# MCXN236 register map
Vendor: nxp.com; File version: 1.0
CPU: CM33 r2p0, little endian, MPU, FPU, VTOR, 3 interrupt priority bits
Registers are 32-bit, read-write, reset 0x0 unless marked. A register's access mark holds for its fields unless they carry their own. Offsets are from the block's base; [hi:lo] are bit positions; {n}, {i} and the like mark numbered series; 'fields as' and 'values as' point back to an identical list.

## PUF_CTRL — PUF Key Context Management
Base 0x4002C000; alternate view of PUF
Same registers: PUF_CTRL_ALIAS1 0x4002D000 (alternate view of PUF_ALIAS1), PUF_CTRL_ALIAS2 0x4002E000 (alternate view of PUF_ALIAS2), PUF_CTRL_ALIAS3 0x4002F000 (alternate view of PUF_ALIAS3)
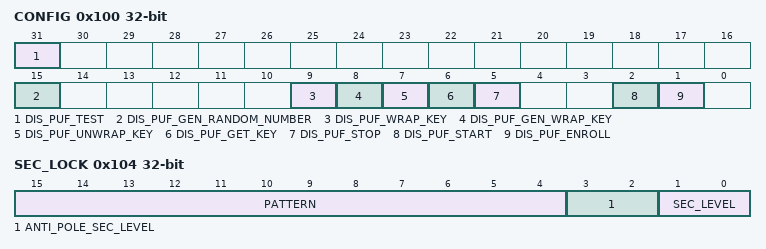
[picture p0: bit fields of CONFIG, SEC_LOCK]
0x100 CONFIG — PUF command blocking configuration
  [all] fields
    0=ENABLE (Command enabled); 1=DISABLE (Command disabled)
  [31] DIS_PUF_TEST — Disable PUF test command
  [15] DIS_PUF_GEN_RANDOM_NUMBER — Disable PUF generate and wrap key command
  [9] DIS_PUF_WRAP_KEY — Disable PUF wrap key command
  [8] DIS_PUF_GEN_WRAP_KEY — Disable PUF generate and wrap key command
  [7] DIS_PUF_UNWRAP_KEY — Disable PUF unwrap key command
  [6] DIS_PUF_GET_KEY — Disable PUF get key command
  [5] DIS_PUF_STOP — Disable PUF stop command
  [2] DIS_PUF_START — Disable PUF start command
  [1] DIS_PUF_ENROLL — Disable PUF enroll command
0x104 SEC_LOCK — Security level lock
  [15:4] PATTERN
  [3:2] ANTI_POLE_SEC_LEVEL — Anti-pole of security level
    0=NONSECURE_NONPRIV_MASTER (Secure and privileged Master); 1=NONSECURE_PRIV_MASTER (Secure and non-privileged Master); 2=SECURE_NONPRIV_MASTER (Non-secure and privileged Master); 3=SECURE_PRIV_MASTER (Non-secure and non-privileged Master)
  [1:0] SEC_LEVEL — Security Level
    0=NONSECURE_NONPRIV_MASTER (Non-secure and non-privileged Master); 1=NONSECURE_PRIV_MASTER (Non-secure and privileged Master); 2=SECURE_NONPRIV_MASTER (Secure and non-privileged Master); 3=SECURE_PRIV_MASTER (Secure and privileged Master)
0x108 APP_CTX_MASK — Application defined context mask
  [31:0] APP_CTX_MASK — Application defined context

## SMARTDMA0 — SmartDMA
Base 0x40033000
0x20 BOOTADR — Boot Address
  [31:2] ADDR — 32-bit boot address, the boot address should be 4-byte aligned.
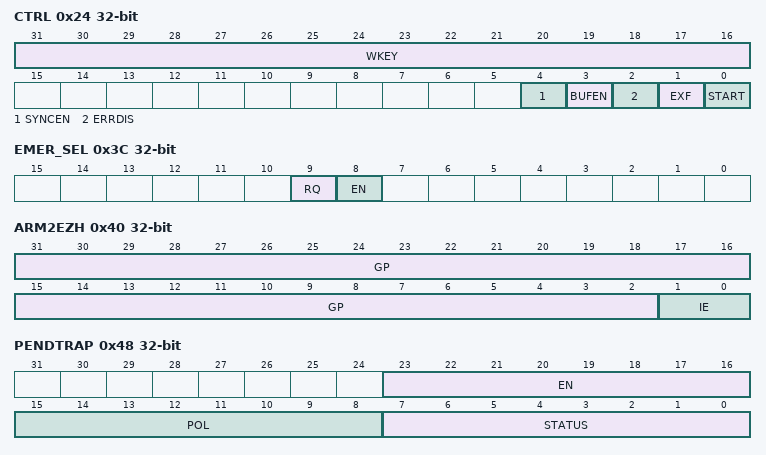
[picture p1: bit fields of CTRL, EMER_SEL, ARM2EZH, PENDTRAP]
0x24 CTRL — Control
  [31:16] WKEY — Write Key
  [4] SYNCEN — Sync Enable
  [3] BUFEN — Buffer Enable
  [2] ERRDIS — Error Disable
  [1] EXF — External Flag
  [0] START — Start Bit Ignition
0x28 PC ro — Program Counter
0x2C SP ro — Stack Pointer
0x30 BREAK_ADDR — Breakpoint Address
  [31:2] ADDR — 32-bit address to swap to EZHB_BREAK_VECT location
0x34 BREAK_VECT — Breakpoint Vector
  [31:2] VEC — Vector address of user debug routine.
0x38 EMER_VECT — Emergency Vector
  [31:2] VEC — Vector address of emergency code routine
0x3C EMER_SEL — Emergency Select
  [9] RQ — Software emergency request
  [8] EN — Emergency code routine
0x40 ARM2EZH — ARM to EZH Interrupt Control
  [31:2] GP — General purpose register bits
  [1:0] IE — Interrupt Enable
0x44 EZH2ARM — EZH to ARM Trigger
  [31:0] GP — General purpose register bits Writing to EZH2ARM triggers the ARM interrupt when ARM2EZH [1:0] == 2h
0x48 PENDTRAP — Pending Trap Control
  [23:16] EN — Enable Pending Trap
  [15:8] POL — Polarity
  [7:0] STATUS — Status Flag or Pending Trap Request

## PORT5 — PORT
Base 0x40042000
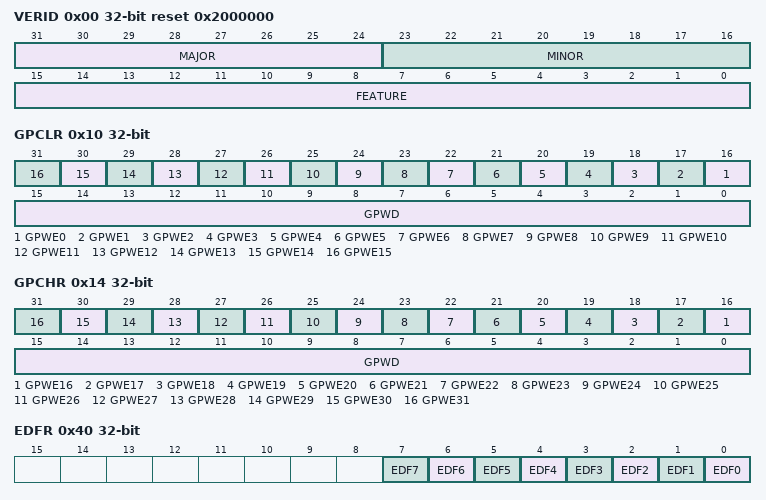
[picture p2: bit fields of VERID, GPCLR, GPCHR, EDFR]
0x00 VERID ro reset 0x2000000 — Version ID
  [31:24] MAJOR — Major Version Number
  [23:16] MINOR — Minor Version Number
  [15:0] FEATURE — Feature Specification Number
    0=Basic implementation
0x10 GPCLR — Global Pin Control Low
  [n+16] GPWE{n} (n=0..15) — Global Pin Write Enable
    0=gpwe0 (Not updated); 1=gpwe1 (Updated)
  [15:0] GPWD — Global Pin Write Data
0x14 GPCHR — Global Pin Control High
  [n] GPWE{n} (n=16..31) — Global Pin Write Enable
    0=gpwe0 (Not updated); 1=gpwe1 (Updated)
  [15:0] GPWD — Global Pin Write Data
0x20 CONFIG — Configuration
  [0] RANGE — Port Voltage Range
    0=1.71 V-3.6 V; 1=2.70 V-3.6 V
0x40 EDFR ro — EFT Detect Flag
  [all] fields
    0=edie0 (No EFT event detected); 1=edie1 (High or/and low EFT event detected)
  [n] EDF{n} (n=0..7) — EFT Detect Flag
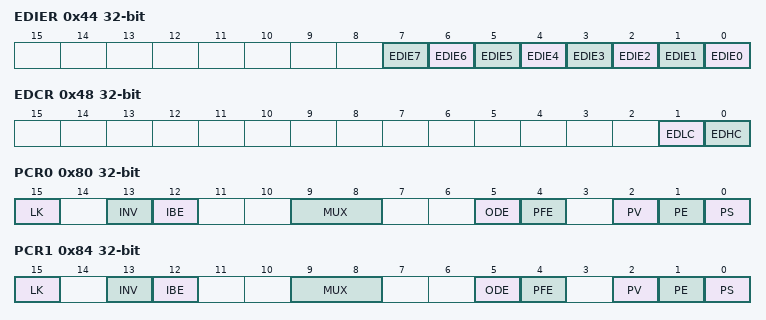
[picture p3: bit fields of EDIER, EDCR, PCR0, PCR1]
0x44 EDIER — EFT Detect Interrupt Enable
  [all] fields
    0=edie0 (Interrupt not generated upon detection of the EFT event); 1=edie1 (Interrupt generated upon detection of the EFT event)
  [n] EDIE{n} (n=0..7) — EFT Detect Interrupt Enable
0x48 EDCR — EFT Detect Clear
  [1] EDLC — EFT Detect Low Clear
    0=Does not clear; 1=Clears
  [0] EDHC — EFT Detect High Clear
    0=Does not clear; 1=Clears
0x80 PCR0 — Pin Control 0
  [15] LK — Lock Register
    0=Does not lock; 1=Locks
  [13] INV — Invert Input
    0=Does not invert; 1=Inverts
  [12] IBE — Input Buffer Enable
    0=Disables; 1=Enables
  [9:8] MUX — Pin Multiplex Control
    0=Alternative 0 (GPIO); 1=Alternative 1 (chip-specific); 2=Alternative 2 (chip-specific); 3=Alternative 3 (chip-specific)
  [5] ODE — Open Drain Enable
    0=Disables; 1=Enables
  [4] PFE — Passive Filter Enable
    0=Disables; 1=Enables
  [2] PV — Pull Value
    0=Low; 1=High
  [1] PE — Pull Enable
    0=Disables; 1=Enables
  [0] PS — Pull Select
    0=Enables internal pulldown resistor; 1=Enables internal pullup resistor
0x84 PCR1 — Pin Control 1
  fields as PCR0
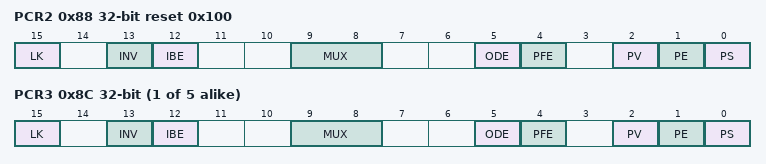
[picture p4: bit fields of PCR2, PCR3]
0x88 PCR2 reset 0x100 — Pin Control 2
  fields as PCR0
{0x80+4i} PCR{i} (i=3..7) — Pin Control {i}
  fields as PCR0
